# ESP32S31_RADIO register map
Vendor: Espressif; Series: ESP32-S31; File version: 3.52
Registers are 32-bit, read-write, no defined reset value unless marked. A register's access mark holds for its fields unless they carry their own. Offsets are from the block's base; [hi:lo] are bit positions; {n}, {i} and the like mark numbered series.

## PHY_BTAGC_RECOVERED — Sparse BTAGC words absent from the public platform PAC.
Base 0x20102800
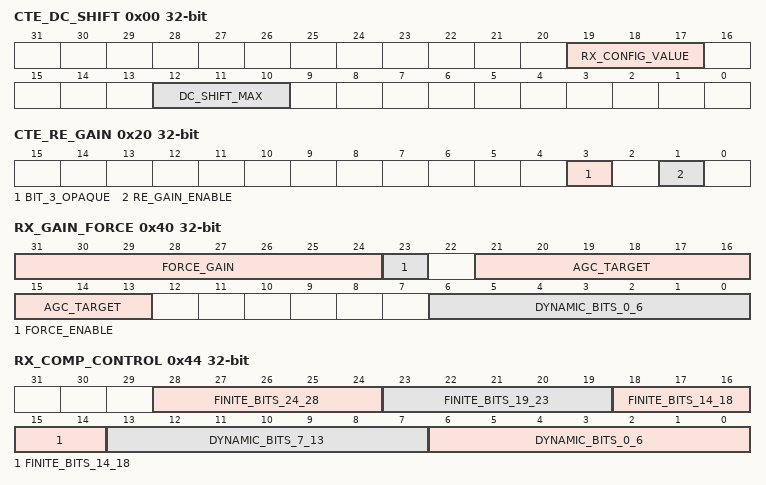
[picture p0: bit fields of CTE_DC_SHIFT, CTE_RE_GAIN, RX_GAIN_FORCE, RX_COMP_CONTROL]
0x00 CTE_DC_SHIFT — Project-assigned name. Bluetooth CTE DC-shift limit control; only the independently named three-bit maximum field is assigned.
  [19:17] RX_CONFIG_VALUE — Project-assigned name. bt_bb_rx_set replaces this field with the finite value 7. No narrower hardware meaning is claimed.
  [12:10] DC_SHIFT_MAX — Project-assigned name.
0x20 CTE_RE_GAIN — Project-assigned name. Bluetooth CTE receive-gain control; the setter unconditionally sets the exposed enable bit.
  [3] BIT_3_OPAQUE — Opaque: meaning not established. bt_agc_sat_gain, tail-called by bt_bb_v2_rx_set, clears this positional bit in one fresh-read RMW; its hardware meaning remains unknown.
  [1] RE_GAIN_ENABLE — Project-assigned name.
0x40 RX_GAIN_FORCE — Bluetooth receive gain force word. Complete ROM phy_rx_gain_force forces the gain through FORCE_GAIN and FORCE_ENABLE; ble_bb_set_agc_target_value and bt_agc_target_set write AGC_TARGET.
  [31:24] FORCE_GAIN — Complete ROM phy_rx_gain_force and librftest force_rx_gain replace this byte with the caller's gain.
  [23] FORCE_ENABLE — Complete ROM phy_rx_gain_force and librftest force_rx_gain write the low bit of the caller's flags here after the forced gain.
  [21:13] AGC_TARGET — Complete ble_bb_set_agc_target_value replaces this field with its argument and ble_bb_get_agc_target_value reads it back; bt_agc_target_set writes the finite image 0x1d4.
  [6:0] DYNAMIC_BITS_0_6 — Project-assigned name. bt_agc_gain_set replaces this field with the low seven bits of the byte read from the linked phy_param image at offset 0x120.
0x44 RX_COMP_CONTROL — Project-assigned name. Complete bt_set_rx_comp updates five non-overlapping fields; the two low fields are dynamic and the three higher fields receive finite images.
  [28:24] FINITE_BITS_24_28 — Project-assigned name. The leaf replaces this field with 6.
  [23:19] FINITE_BITS_19_23 — Project-assigned name. The leaf replaces this field with 0.
  [18:14] FINITE_BITS_14_18 — Project-assigned name. The leaf replaces this field with 8.
  [13:7] DYNAMIC_BITS_7_13 — Project-assigned name. The leaf replaces this exact field with a dynamic image.
  [6:0] DYNAMIC_BITS_0_6 — Project-assigned name. The leaf replaces this exact field with a dynamic image.
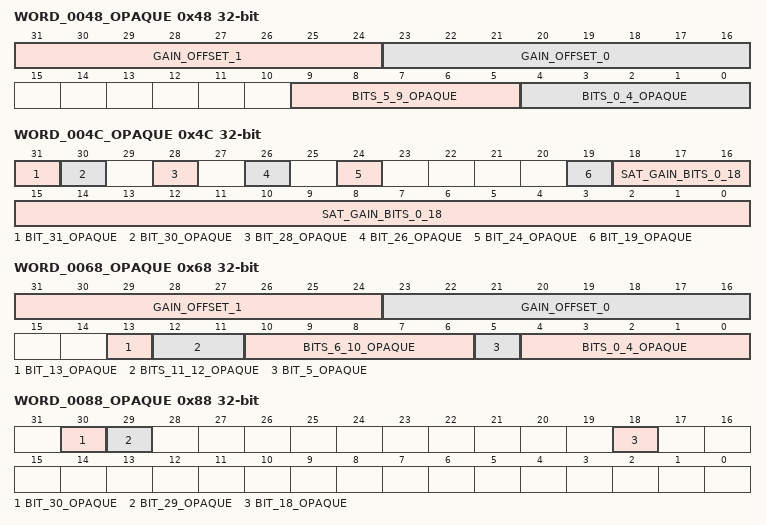
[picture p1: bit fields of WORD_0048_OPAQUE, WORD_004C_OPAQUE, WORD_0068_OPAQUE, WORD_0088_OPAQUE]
0x48 WORD_0048_OPAQUE — Opaque: meaning not established. Complete bt_set_rx_comp and bt_agc_gain_offset read-modify-write four positional fields; individual hardware meanings remain unnamed.
  [31:24] GAIN_OFFSET_1 — Project-assigned name.
  [23:16] GAIN_OFFSET_0 — Project-assigned name.
  [9:5] BITS_5_9_OPAQUE — Opaque: meaning not established.
  [4:0] BITS_0_4_OPAQUE — Opaque: meaning not established.
0x4C WORD_004C_OPAQUE — Opaque: meaning not established. Bluetooth receive setup clears bit 26. bt_agc_sat_gain, tail-called by bt_bb_v2_rx_set, later replaces bits 18:0 and sets bits 19, 24, 26, 28, 30 and 31 in two fresh-read RMW operations.
  [31] BIT_31_OPAQUE — Opaque: meaning not established. bt_agc_sat_gain, tail-called by bt_bb_v2_rx_set, sets this positional bit in one fresh-read RMW; its hardware meaning remains unknown.
  [30] BIT_30_OPAQUE — Opaque: meaning not established. bt_agc_sat_gain, tail-called by bt_bb_v2_rx_set, sets this positional bit in one fresh-read RMW; its hardware meaning remains unknown.
  [28] BIT_28_OPAQUE — Opaque: meaning not established. bt_agc_sat_gain, tail-called by bt_bb_v2_rx_set, sets this positional bit in one fresh-read RMW; its hardware meaning remains unknown.
  [26] BIT_26_OPAQUE — Opaque: meaning not established. Bluetooth receive setup clears this positional bit; bt_agc_sat_gain sets it again. Its hardware meaning remains unknown.
  [24] BIT_24_OPAQUE — Opaque: meaning not established. bt_agc_sat_gain, tail-called by bt_bb_v2_rx_set, sets this positional bit in one fresh-read RMW; its hardware meaning remains unknown.
  [19] BIT_19_OPAQUE — Opaque: meaning not established. bt_agc_sat_gain, tail-called by bt_bb_v2_rx_set, sets this positional bit in one fresh-read RMW; its hardware meaning remains unknown.
  [18:0] SAT_GAIN_BITS_0_18 — Project-assigned name. bt_agc_sat_gain replaces these positional bits with the finite image 0x1770 in one fresh-read RMW; their hardware meaning remains unknown.
0x50 AGC_GAIN_MAX_CONTROL — Project-assigned name. Complete bt_agc_gain_max replaces bits 20:14 with one dynamic image while preserving all other bits.
  [20:14] AGC_GAIN_MAX — Complete bt_agc_gain_max replaces this field with its argument.
0x54 AGC_GAIN_IMAGE — Project-assigned name. Complete bt_agc_gain_set replaces one seven-bit field derived from the linked phy_param byte at offset 0x120 and preserves every other bit.
  [8:2] DYNAMIC_BITS_2_8 — Project-assigned name. Exact seven-bit image produced by subtracting five from the linked phy_param byte and retaining the low seven bits.
0x58 AGC_SAT_GAIN_IMAGE_0 wo — Project-assigned name. Complete bt_agc_sat_gain writes argument 0 as the complete register image. The dynamic image remains register-level evidence.
0x5C AGC_SAT_GAIN_IMAGE_1 wo — Project-assigned name. Complete bt_agc_sat_gain writes argument 0 as the complete register image. The dynamic image remains register-level evidence.
0x64 AGC_SAT_GAIN_CONFIG wo — Project-assigned name. Complete bt_agc_sat_gain writes the complete finite image 0x00000404.
0x68 WORD_0068_OPAQUE — Opaque: meaning not established. Complete bt_agc_gain_offset and bt_agc_recorrect_set read-modify-write seven positional fields; individual hardware meanings remain unnamed.
  [31:24] GAIN_OFFSET_1 — Project-assigned name.
  [23:16] GAIN_OFFSET_0 — Project-assigned name.
  [13] BIT_13_OPAQUE — Opaque: meaning not established.
  [12:11] BITS_11_12_OPAQUE — Opaque: meaning not established.
  [10:6] BITS_6_10_OPAQUE — Opaque: meaning not established.
  [5] BIT_5_OPAQUE — Opaque: meaning not established.
  [4:0] BITS_0_4_OPAQUE — Opaque: meaning not established.
0x6C WORD_006C_OPAQUE — Opaque: meaning not established. Complete bt_agc_recorrect_set replaces the high byte with one finite image.
  [31:24] FINITE_BITS_24_31 — Project-assigned name. The leaf replaces this field with 0x0f.
0x84 WORD_0084_OPAQUE — Opaque: meaning not established. Complete bt_agc_restart_set replaces the high byte with one finite image.
  [31:24] FINITE_BITS_24_31 — Project-assigned name. The leaf replaces this field with 0xf4.
0x88 WORD_0088_OPAQUE — Opaque: meaning not established. Bluetooth receive setup clears bit 29 and sets bit 18 through separate fresh-read operations. bt_agc_restart_set clears bit 30 and bt_agc_sat_gain sets it again.
  [30] BIT_30_OPAQUE — Opaque: meaning not established.
  [29] BIT_29_OPAQUE — Opaque: meaning not established.
  [18] BIT_18_OPAQUE — Opaque: meaning not established.
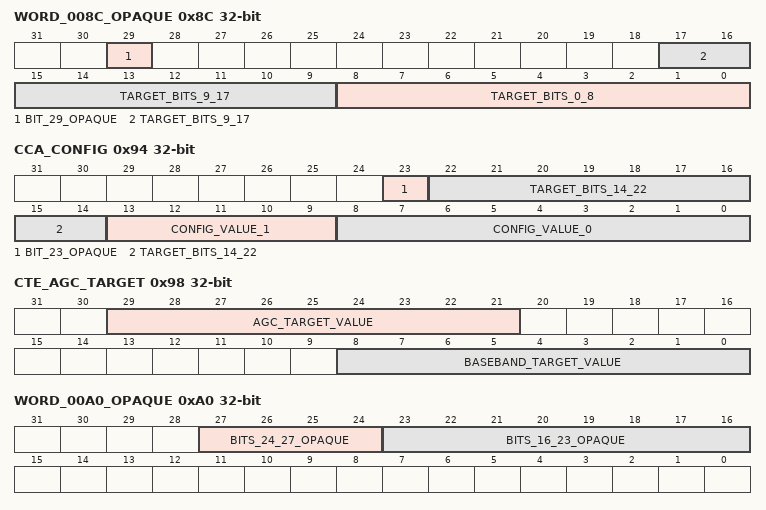
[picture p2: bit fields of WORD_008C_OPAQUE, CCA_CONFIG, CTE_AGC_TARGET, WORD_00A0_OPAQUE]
0x8C WORD_008C_OPAQUE — Opaque: meaning not established. Bluetooth receive setup and target configuration update three disjoint positional fields and clear one independently observed control bit.
  [29] BIT_29_OPAQUE — Opaque: meaning not established.
  [17:9] TARGET_BITS_9_17 — Project-assigned name. bt_agc_target_set replaces this positional field with the finite image 0x1dc.
  [8:0] TARGET_BITS_0_8 — Project-assigned name. bt_agc_target_set replaces this positional field with the finite image 0x1d4.
0x94 CCA_CONFIG — Project-assigned name. Finite Bluetooth clear-channel-assessment defaults written by bt_bb_cca_config. Untouched fields remain unassigned.
  [23] BIT_23_OPAQUE — Opaque: meaning not established.
  [22:14] TARGET_BITS_14_22 — Project-assigned name. bt_agc_target_set replaces this positional field with the finite image 0x1ce.
  [13:9] CONFIG_VALUE_1 — Project-assigned name. Five-bit finite value 0x1E.
  [8:0] CONFIG_VALUE_0 — Project-assigned name. Nine-bit finite value 0x1CE.
0x98 CTE_AGC_TARGET — Project-assigned name. Bluetooth CTE AGC target word; only the independently named nine-bit target field is assigned.
  [29:21] AGC_TARGET_VALUE — Project-assigned name.
  [8:0] BASEBAND_TARGET_VALUE — Project-assigned name. bt_agc_target_set replaces this disjoint low field with the finite image 0x1d4.
0xA0 WORD_00A0_OPAQUE — Opaque: meaning not established. Complete bt_bb_set_rx_sense publishes a complete dynamic image. Independent finite RMWs replace two positional fields used by the bounded baseband initializer.
  [27:24] BITS_24_27_OPAQUE — Opaque: meaning not established.
  [23:16] BITS_16_23_OPAQUE — Opaque: meaning not established.
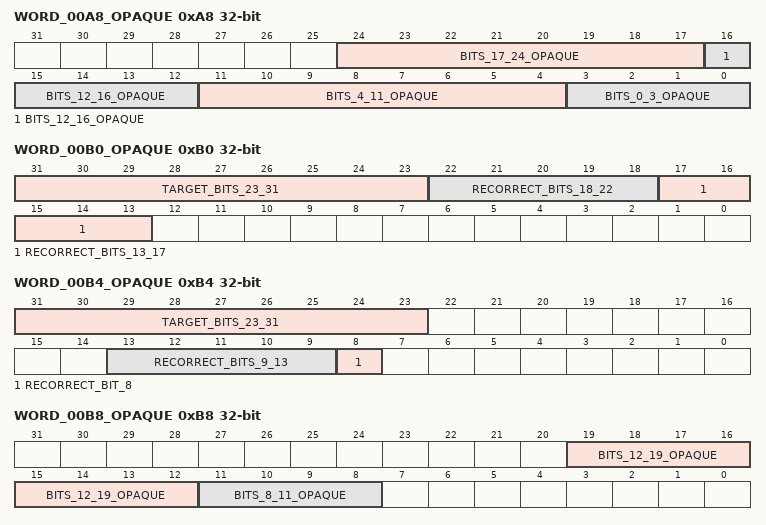
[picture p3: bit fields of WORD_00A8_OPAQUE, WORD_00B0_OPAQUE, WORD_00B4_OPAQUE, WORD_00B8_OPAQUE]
0xA8 WORD_00A8_OPAQUE — Opaque: meaning not established. Complete bt_bb_set_rx_sense publishes a complete dynamic image. Independent finite RMWs replace four positional fields used by the bounded baseband initializer.
  [24:17] BITS_17_24_OPAQUE — Opaque: meaning not established.
  [16:12] BITS_12_16_OPAQUE — Opaque: meaning not established.
  [11:4] BITS_4_11_OPAQUE — Opaque: meaning not established.
  [3:0] BITS_0_3_OPAQUE — Opaque: meaning not established.
0xB0 WORD_00B0_OPAQUE — Opaque: meaning not established. Finite images written by complete bt_agc_recorrect_set and bt_agc_target_set leaves.
  [31:23] TARGET_BITS_23_31 — Project-assigned name. bt_agc_target_set replaces this field with 0x1d4.
  [22:18] RECORRECT_BITS_18_22 — Project-assigned name. bt_agc_recorrect_set replaces this field with 0x18.
  [17:13] RECORRECT_BITS_13_17 — Project-assigned name. bt_agc_recorrect_set replaces this field with 0x18.
0xB4 WORD_00B4_OPAQUE — Opaque: meaning not established. Finite images written by complete bt_agc_recorrect_set and bt_agc_target_set leaves.
  [31:23] TARGET_BITS_23_31 — Project-assigned name. bt_agc_target_set replaces this field with 0x1ce.
  [13:9] RECORRECT_BITS_9_13 — Project-assigned name. bt_agc_recorrect_set replaces this field with 0x0a.
  [8] RECORRECT_BIT_8 — Project-assigned name. bt_agc_recorrect_set sets this bit.
0xB8 WORD_00B8_OPAQUE — Opaque: meaning not established. Complete bt_bb_set_rx_sense publishes a complete dynamic image. Independent finite RMWs replace two positional fields used by the bounded baseband initializer.
  [19:12] BITS_12_19_OPAQUE — Opaque: meaning not established.
  [11:8] BITS_8_11_OPAQUE — Opaque: meaning not established.
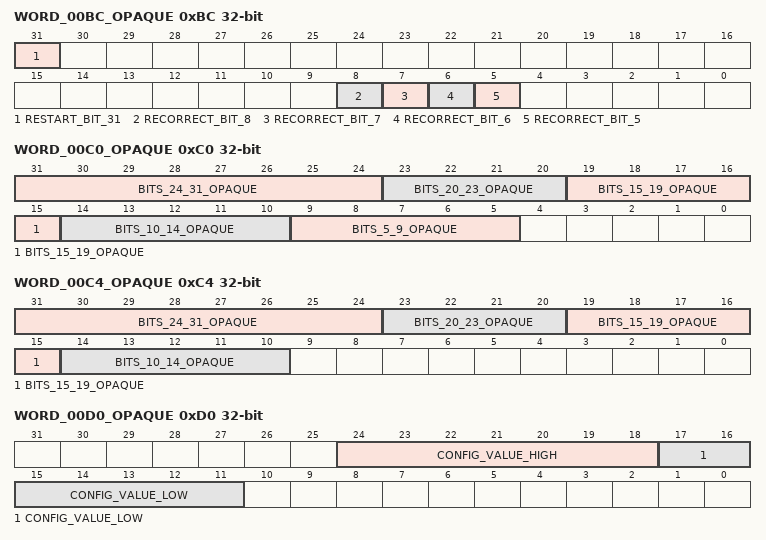
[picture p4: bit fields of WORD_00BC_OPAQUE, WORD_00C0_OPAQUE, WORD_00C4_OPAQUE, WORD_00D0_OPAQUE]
0xBC WORD_00BC_OPAQUE — Opaque: meaning not established. Complete recorrect and restart leaves independently update five observed control bits.
  [31] RESTART_BIT_31 — Project-assigned name. bt_agc_restart_set sets this bit.
  [8] RECORRECT_BIT_8 — Project-assigned name. bt_agc_recorrect_set clears this bit.
  [7] RECORRECT_BIT_7 — Project-assigned name. bt_agc_recorrect_set sets this bit.
  [6] RECORRECT_BIT_6 — Project-assigned name. bt_agc_recorrect_set clears this bit.
  [5] RECORRECT_BIT_5 — Project-assigned name. bt_agc_recorrect_set sets this bit.
0xC0 WORD_00C0_OPAQUE — Opaque: meaning not established. Complete bt_agc_detect_set replaces five positional fields with finite images.
  [31:24] BITS_24_31_OPAQUE — Opaque: meaning not established. The leaf replaces this field with 0x9c.
  [23:20] BITS_20_23_OPAQUE — Opaque: meaning not established. The leaf replaces this field with 7.
  [19:15] BITS_15_19_OPAQUE — Opaque: meaning not established. The leaf replaces this field with 0x0a.
  [14:10] BITS_10_14_OPAQUE — Opaque: meaning not established. The leaf replaces this field with 0x0a.
  [9:5] BITS_5_9_OPAQUE — Opaque: meaning not established. The leaf replaces this field with 0x0a.
0xC4 WORD_00C4_OPAQUE — Opaque: meaning not established. Complete bt_agc_detect_set replaces four positional fields with finite images.
  [31:24] BITS_24_31_OPAQUE — Opaque: meaning not established. The leaf replaces this field with 0x9c.
  [23:20] BITS_20_23_OPAQUE — Opaque: meaning not established. The leaf replaces this field with 0x0a.
  [19:15] BITS_15_19_OPAQUE — Opaque: meaning not established. The leaf replaces this field with 0x0f.
  [14:10] BITS_10_14_OPAQUE — Opaque: meaning not established. The leaf replaces this field with 0x0f.
0xD0 WORD_00D0_OPAQUE — Opaque: meaning not established. bt_agc_v2_set replaces two seven-bit fields with the finite value 20.
  [24:18] CONFIG_VALUE_HIGH — Project-assigned name.
  [17:11] CONFIG_VALUE_LOW — Project-assigned name.
0xD4 WORD_00D4_OPAQUE — Opaque: meaning not established. bt_agc_v2_set replaces bits 24:6 with the finite image 0x003C0.
  [24:6] CONFIG_VALUE — Project-assigned name.
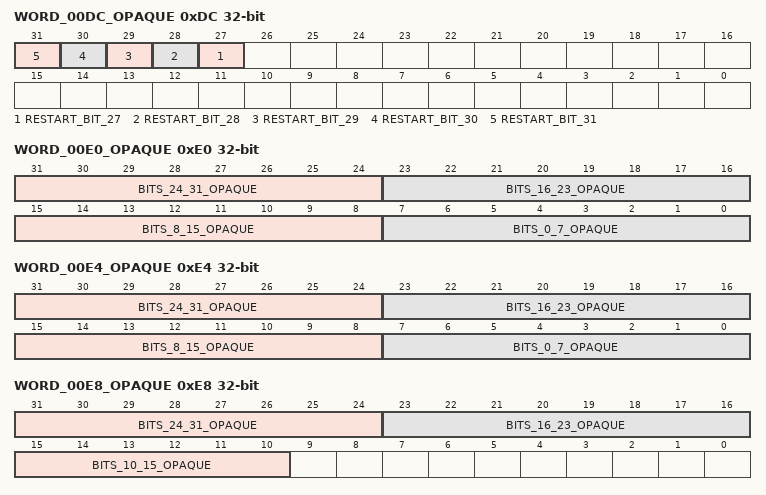
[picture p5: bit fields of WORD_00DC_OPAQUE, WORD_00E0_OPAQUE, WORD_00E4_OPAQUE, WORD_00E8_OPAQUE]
0xDC WORD_00DC_OPAQUE — Opaque: meaning not established. Complete bt_agc_restart_set sets five independently observed high control bits through separate fresh-read RMW operations.
  [n] RESTART_BIT_{n} (n=27..31) — Project-assigned name. The leaf sets this bit.
0xE0 WORD_00E0_OPAQUE — Opaque: meaning not established. Four positional byte images written by complete bt_agc_restart_set.
  [31:24] BITS_24_31_OPAQUE — Opaque: meaning not established. The leaf replaces this field with 0x14.
  [23:16] BITS_16_23_OPAQUE — Opaque: meaning not established. The leaf replaces this field with 0x0e.
  [15:8] BITS_8_15_OPAQUE — Opaque: meaning not established. The leaf replaces this field with 0x0e.
  [7:0] BITS_0_7_OPAQUE — Opaque: meaning not established. The leaf replaces this field with 0x0f.
0xE4 WORD_00E4_OPAQUE — Opaque: meaning not established. Four positional byte images written by complete bt_agc_restart_set.
  [31:24] BITS_24_31_OPAQUE — Opaque: meaning not established. The leaf replaces this field with 0x1e.
  [23:16] BITS_16_23_OPAQUE — Opaque: meaning not established. The leaf replaces this field with 0xec.
  [15:8] BITS_8_15_OPAQUE — Opaque: meaning not established. The leaf replaces this field with 0xf2.
  [7:0] BITS_0_7_OPAQUE — Opaque: meaning not established. The leaf replaces this field with 0xf2.
0xE8 WORD_00E8_OPAQUE — Opaque: meaning not established. Three positional finite images written by complete bt_agc_restart_set; bits 9:0 remain unassigned.
  [31:24] BITS_24_31_OPAQUE — Opaque: meaning not established. The leaf replaces this field with 0xf1.
  [23:16] BITS_16_23_OPAQUE — Opaque: meaning not established. The leaf replaces this field with 0xe2.
  [15:10] BITS_10_15_OPAQUE — Opaque: meaning not established. The leaf replaces this field with 3.
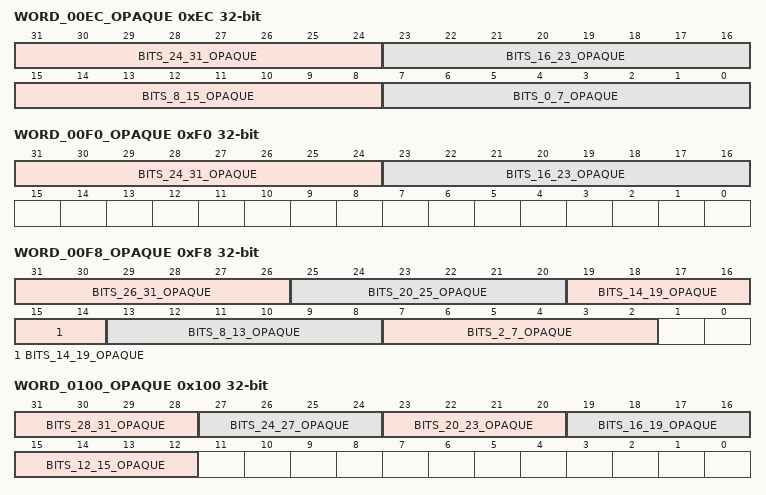
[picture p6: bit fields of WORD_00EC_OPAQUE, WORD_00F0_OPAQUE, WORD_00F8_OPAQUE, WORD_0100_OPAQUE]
0xEC WORD_00EC_OPAQUE — Opaque: meaning not established. Four positional byte images written by complete bt_agc_restart_set.
  [31:24] BITS_24_31_OPAQUE — Opaque: meaning not established. The leaf replaces this field with 0x2d.
  [23:16] BITS_16_23_OPAQUE — Opaque: meaning not established. The leaf replaces this field with 0x28.
  [15:8] BITS_8_15_OPAQUE — Opaque: meaning not established. The leaf replaces this field with 0xd3.
  [7:0] BITS_0_7_OPAQUE — Opaque: meaning not established. The leaf replaces this field with 0xd8.
0xF0 WORD_00F0_OPAQUE — Opaque: meaning not established. Two positional high-byte images written by complete bt_agc_restart_set; bits 15:0 remain unassigned.
  [31:24] BITS_24_31_OPAQUE — Opaque: meaning not established. The leaf replaces this field with 0xa6.
  [23:16] BITS_16_23_OPAQUE — Opaque: meaning not established. The leaf replaces this field with 0xa6.
0xF8 WORD_00F8_OPAQUE — Opaque: meaning not established. Five positional six-bit images written by complete bt_agc_restart_set; bits 1:0 remain unassigned.
  [31:26] BITS_26_31_OPAQUE — Opaque: meaning not established. The leaf replaces this field with 0x0c.
  [25:20] BITS_20_25_OPAQUE — Opaque: meaning not established. The leaf replaces this field with 5.
  [19:14] BITS_14_19_OPAQUE — Opaque: meaning not established. The leaf replaces this field with 0x20.
  [13:8] BITS_8_13_OPAQUE — Opaque: meaning not established. The leaf replaces this field with 0x0c.
  [7:2] BITS_2_7_OPAQUE — Opaque: meaning not established. The leaf replaces this field with 0x0c.
0x100 WORD_0100_OPAQUE — Opaque: meaning not established. Five positional high-nibble images written by complete bt_agc_restart_set; bits 11:0 remain unassigned.
  [31:28] BITS_28_31_OPAQUE — Opaque: meaning not established. The leaf replaces this field with 6.
  [27:24] BITS_24_27_OPAQUE — Opaque: meaning not established. The leaf replaces this field with 6.
  [23:20] BITS_20_23_OPAQUE — Opaque: meaning not established. The leaf replaces this field with 6.
  [19:16] BITS_16_19_OPAQUE — Opaque: meaning not established. The leaf replaces this field with 8.
  [15:12] BITS_12_15_OPAQUE — Opaque: meaning not established. The leaf replaces this field with 0x0a.
